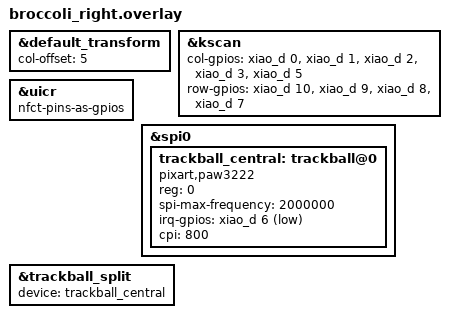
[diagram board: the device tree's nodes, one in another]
#include "broccoli.dtsi"

&default_transform {
    col-offset = <5>;
};

&kscan {
    col-gpios
        = <&xiao_d 0 GPIO_ACTIVE_HIGH>
        , <&xiao_d 1 GPIO_ACTIVE_HIGH>
        , <&xiao_d 2 GPIO_ACTIVE_HIGH>
        , <&xiao_d 3 GPIO_ACTIVE_HIGH>
        , <&xiao_d 5 GPIO_ACTIVE_HIGH>
        ;
    row-gpios
        = <&xiao_d 10 (GPIO_ACTIVE_HIGH | GPIO_PULL_DOWN)>
        , <&xiao_d 9 (GPIO_ACTIVE_HIGH | GPIO_PULL_DOWN)>
        , <&xiao_d 8 (GPIO_ACTIVE_HIGH | GPIO_PULL_DOWN)>
        , <&xiao_d 7 (GPIO_ACTIVE_HIGH | GPIO_PULL_DOWN)>
        ;
};

&uicr {
    nfct-pins-as-gpios;
};

&spi0 {
    status = "okay";

    trackball_central: trackball@0 {
        compatible = "pixart,paw3222";
        reg = <0>;
        status = "okay";

        spi-max-frequency = <2000000>;
        irq-gpios = <&xiao_d 6 (GPIO_ACTIVE_LOW | GPIO_PULL_UP)>;
        cpi = <800>;
    };
};

&trackball_split {
    device = <&trackball_central>;
};
